# FM33LC0XX register map
File version: 1.0
ARM 32-bit Cortex SC000 Microcontroller based device
CPU: SC123, little endian, no MPU, no FPU, 3 interrupt priority bits
Registers are 32-bit, read-write, reset 0x0 unless marked. A register's access mark holds for its fields unless they carry their own. Offsets are from the block's base; lines under a group give offsets from that group; [hi:lo] are bit positions; {n}, {i} and the like mark numbered series; 'fields as' and 'values as' point back to an identical list; <NAME> marks a mode.

## Memory map
? ?
0x40000000 DBG size 0x8 — DBG module information
0x40000100 PMU size 0x14 — PMU module information
0x40000200 RCC size 0x7C — RCC module information
0x40000400 DMA size 0x4C — DMA module information
0x40000C00 GPIOA size 0x2C — GPIOA module information
0x40000C40 GPIOB size 0x2C — GPIOB module information
0x40000C80 GPIOC size 0x2C — GPIOC module information
0x40000CC0 GPIOD size 0x2C — GPIOD module information
0x40000D00 GPIO size 0x204 — GPIO module information
0x40001000 FLS size 0x24 — FLS module information
0x40010000 U7816 size 0x24 — U7816 module information
0x40010400 LPUART0 size 0x1C — LPUART0 module information
0x40010800 SPI2 size 0x1C — SPI2 module information
0x40010C00 LCD size 0x58 — LCD module information
0x40011000 RTC size 0x90 — RTC module information
0x40011400 IWDT size 0x18 — IWDT module information
0x40011800 WWDT size 0x18 — WWDT module information
0x40011C00 UART0 size 0x1C — UART0 module information
0x40012000 UART1 size 0x1C — UART1 module information
0x40012400 I2C size 0x3C — I2C module information
0x40013400 LPTIM size 0x28 — LPTIM module information
0x40013800 GPTIM0 size 0x64 — GPTIM0 module information
0x40013C00 GPTIM1 size 0x64 — GPTIM1 module information
0x40018000 CRC size 0x20 — CRC module information
0x40018400 LPUART1 size 0x1C — LPUART1 module information
0x40018C00 SPI1 size 0x1C — SPI1 module information
0x40019000 HDIV size 0x14 — HDIV module information
0x40019C00 UART size 0x1C — UART module information
0x4001A000 UART4 size 0x1C — UART4 module information
0x4001A400 UART5 size 0x1C — UART5 module information
0x4001A800 RMU size 0x8 — RMU module information
0x4001A80C VREF size 0x10 — VREF module information
0x4001A824 SVD size 0x14 — SVD module information
0x4001A838 FDET size 0x8 — FDET module information
0x4001A844 OPA1 size 0x10 — OPA1 module information
0x4001A854 OPA2 size 0x10 — OPA2 module information
0x4001A868 RNGCTL size 0x4 — RNGCTL module information
0x4001A870 COMP size 0x10 — COMP module information
0x4001AC00 ADC size 0x24 — ADC module information
0x4001B000 ATIM size 0x64 — ATIM module information
0x4001B400 BSTIM size 0x30 — BSTIM module information
0x4001B800 AES size 0x44 — AES module information
0x4001BC00 RNG size 0x1C — RNG module information
0x50000000 USB size 0xDFC — USB module information

## PMU — PMU module information
Base 0x40000100
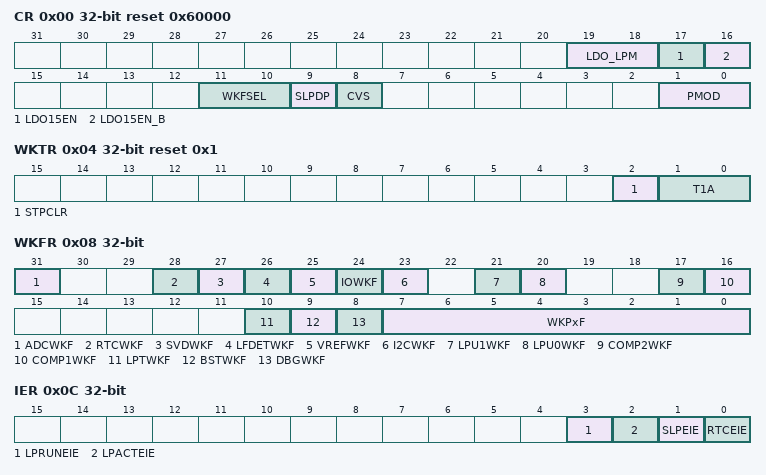
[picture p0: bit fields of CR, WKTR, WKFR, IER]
0x00 CR reset 0x60000 — Power Management Control Register
  [19:18] LDO_LPM — LDO_LPM field description
  [17] LDO15EN ro — LDO15EN field description
  [16] LDO15EN_B ro — LDO15EN_B field description
  [11:10] WKFSEL — WKFSEL field description
  [9] SLPDP — SLPDP field description
  [8] CVS — CVS field description
  [1:0] PMOD — PMOD field description
0x04 WKTR reset 0x1 — Wakeup Time Register
  [2] STPCLR — STPCLR field description
  [1:0] T1A — T1A field description
0x08 WKFR — Wakeup Source Flags Register
  [31] ADCWKF ro — ADCWKF field description
  [28] RTCWKF ro — RTCWKF field description
  [27] SVDWKF ro — SVDWKF field description
  [26] LFDETWKF ro — LFDETWKF field description
  [25] VREFWKF ro — VREFWKF field description
  [24] IOWKF ro — IOWKF field description
  [23] I2CWKF ro — I2CWKF field description
  [21] LPU1WKF ro — LPU1WKF field description
  [20] LPU0WKF ro — LPU0WKF field description
  [17] COMP2WKF ro — COMP2WKF field description
  [16] COMP1WKF ro — COMP1WKF field description
  [10] LPTWKF ro — LPTWKF field description
  [9] BSTWKF ro — BSTWKF field description
  [8] DBGWKF — DBGWKF field description
  [7:0] WKPxF — WKPxF field description
0x0C IER — PMU Interrupt Enable Register
  [3] LPRUNEIE — LPRUNEIE field description
  [2] LPACTEIE — LPACTEIE field description
  [1] SLPEIE — SLPEIE field description
  [0] RTCEIE — RTCEIE field description
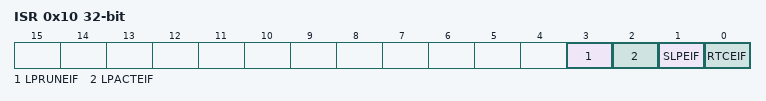
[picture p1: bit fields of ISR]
0x10 ISR — PMU Interrupt and Status Register
  [3] LPRUNEIF — LPRUNEIF field description
  [2] LPACTEIF — LPACTEIF field description
  [1] SLPEIF — SLPEIF field description
  [0] RTCEIF — RTCEIF field description
